# STM32WL5X_CM4 register map
File version: 2.2
CPU: CM4 r0p1, little endian, MPU, no FPU, 4 interrupt priority bits
Registers are 32-bit, read-write, reset 0x0 unless marked. A register's access mark holds for its fields unless they carry their own. Offsets are from the block's base; [hi:lo] are bit positions; lines under a group give offsets from that group; {n}, {i} and the like mark numbered series; 'fields as' and 'values as' point back to an identical list.

## DMA1 — Direct memory access controller
Base 0x40020000
Same registers: DMA2 0x40020400
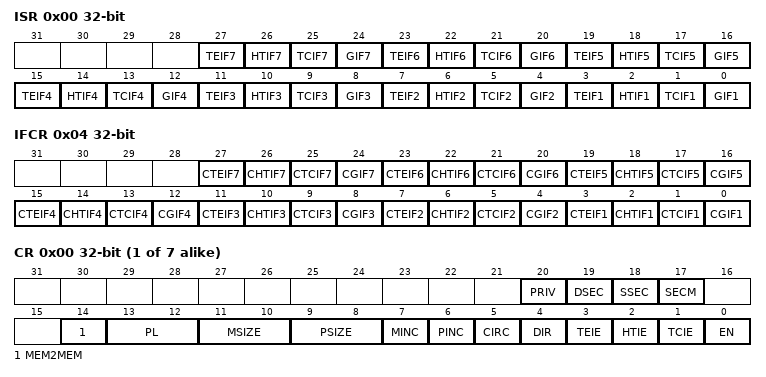
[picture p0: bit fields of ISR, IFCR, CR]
0x00 ISR ro — interrupt status register
  [4n-1] TEIF{n} (n=1..7) — Channel {n} Transfer Error flag
    0=NoError (No transfer error); 1=Error (A transfer error has occured)
  [4n-2] HTIF{n} (n=1..7) — Channel {n} Half Transfer Complete flag
    0=NotHalf (No half transfer event); 1=Half (A half transfer event has occured)
  [4n-3] TCIF{n} (n=1..7) — Channel {n} Transfer Complete flag
    0=NotComplete (No transfer complete event); 1=Complete (A transfer complete event has occured)
  [4n-4] GIF{n} (n=1..7) — Channel {n} Global interrupt flag
    0=NoEvent (No transfer error, half event, complete event); 1=Event (A transfer error, half event or complete event has occured)
0x04 IFCR wo — interrupt flag clear register
  [4n-1] CTEIF{n} (n=1..7) — Channel {n} Transfer Error clear
    1=Clears the TEIF flag in the ISR register
  [4n-2] CHTIF{n} (n=1..7) — Channel {n} Half Transfer clear
    1=Clears the HTIF flag in the ISR register
  [4n-3] CTCIF{n} (n=1..7) — Channel {n} Transfer Complete clear
    1=Clears the TCIF flag in the ISR register
  [4n-4] CGIF{n} (n=1..7) — Channel {n} Global interrupt clear
    1=Clears the GIF, TEIF, HTIF, TCIF flags in the ISR register
0x08 CH{i} (i=1..7; step 0x14) group — Channel cluster: CCR?, CNDTR?, CPAR?, and CMAR? registers
  0x00 CR — channel x configuration register
    [20] PRIV — rivileged mode
      0=Disabled; 1=Enabled
    [19] DSEC — ecurity of the DMA transfer to the destination
    [18] SSEC — ecurity of the DMA transfer from the source
    [17] SECM — ecure mode
    [14] MEM2MEM — memory-to-memory mode
      0=Disabled (Memory to memory mode disabled); 1=Enabled (Memory to memory mode enabled)
    [13:12] PL — priority level
      0=Low (Low priority); 1=Medium priority; 2=High priority; 3=Very high priority
    [11:10] MSIZE — memory size
      0=Bits8 (8-bit size); 1=Bits16 (16-bit size); 2=Bits32 (32-bit size)
    [9:8] PSIZE — peripheral size
      values as MSIZE
    [7] MINC — memory increment mode
      0=Disabled (Increment mode disabled); 1=Enabled (Increment mode enabled)
    [6] PINC — peripheral increment mode
      values as MINC
    [5] CIRC — circular mode
      0=Disabled (Circular buffer disabled); 1=Enabled (Circular buffer enabled)
    [4] DIR — data transfer direction
      0=FromPeripheral (Read from peripheral); 1=FromMemory (Read from memory)
    [3] TEIE — transfer error interrupt enable
      0=Disabled (Transfer Error interrupt disabled); 1=Enabled (Transfer Error interrupt enabled)
    [2] HTIE — half transfer interrupt enable
      0=Disabled (Half Transfer interrupt disabled); 1=Enabled (Half Transfer interrupt enabled)
    [1] TCIE — transfer complete interrupt enable
      0=Disabled (Transfer Complete interrupt disabled); 1=Enabled (Transfer Complete interrupt enabled)
    [0] EN — channel enable
      0=Disabled (Channel disabled); 1=Enabled (Channel enabled)
  0x04 NDTR — channel x number of data to transfer register
    [17:0] NDT — number of data to transfer (0 to 218 - 1)
  0x08 PAR — channel x peripheral address register
    [31:0] PA — peripheral address
  0x0C MAR — channel x memory address register
    [31:0] MA — peripheral address

## GPIOA — General-purpose I/Os
Base 0x48000000
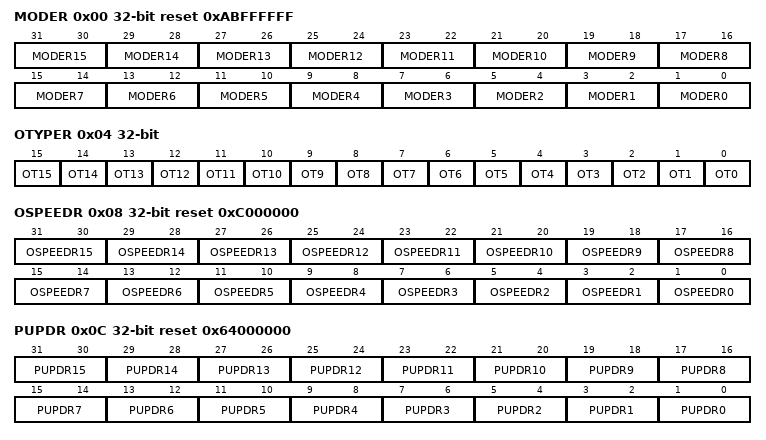
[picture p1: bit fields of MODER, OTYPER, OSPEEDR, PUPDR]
0x00 MODER reset 0xABFFFFFF — GPIO port mode register
  [2n+1:2n] MODER{n} (n=0..15) — Port x configuration pin {n}
    0=Input mode (reset state); 1=Output (General purpose output mode); 2=Alternate function mode; 3=Analog mode
0x04 OTYPER — GPIO port output type register
  [n] OT{n} (n=0..15) — Port x configuration pin {n}
    0=PushPull (Output push-pull (reset state)); 1=OpenDrain (Output open-drain)
0x08 OSPEEDR reset 0xC000000 — GPIO port output speed register
  [2n+1:2n] OSPEEDR{n} (n=0..15) — Port x configuration pin {n}
    0=LowSpeed; 1=MediumSpeed; 2=HighSpeed; 3=VeryHighSpeed
0x0C PUPDR reset 0x64000000 — GPIO port pull-up/pull-down register
  [2n+1:2n] PUPDR{n} (n=0..15) — Port x configuration pin {n}
    0=Floating (No pull-up, pull-down); 1=PullUp; 2=PullDown
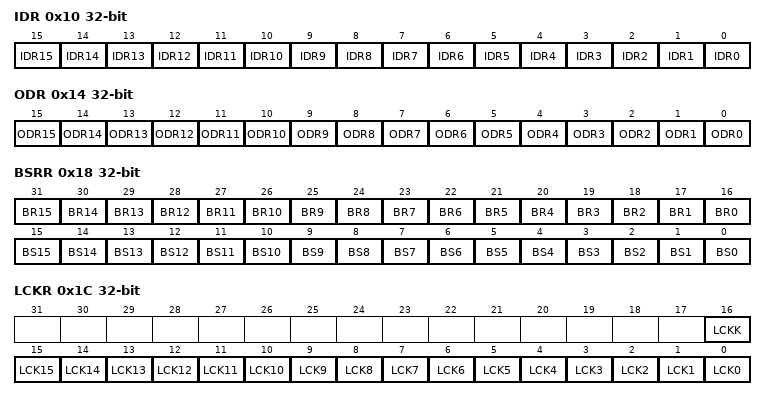
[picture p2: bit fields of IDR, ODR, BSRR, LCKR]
0x10 IDR ro — GPIO port input data register
  [n] IDR{n} (n=0..15) — Port input data pin {n}
    0=Low (Input is logic low); 1=High (Input is logic high)
0x14 ODR — GPIO port output data register
  [n] ODR{n} (n=0..15) — Port output data pin {n}
    0=Low (Set output to logic low); 1=High (Set output to logic high)
0x18 BSRR wo — GPIO port bit set/reset register
  [n+16] BR{n} (n=0..15) — Port x reset pin {n}
    1=Resets the corresponding ODRx bit
  [n] BS{n} (n=0..15) — Port x set pin {n}
    1=Set (Sets the corresponding ODRx bit)
0x1C LCKR — GPIO port configuration lock register
  [16] LCKK — Port x lock bit y (y= 0..15)
    0=NotActive (Port configuration lock key not active); 1=Active (Port configuration lock key active)
  [n] LCK{n} (n=0..15) — Port x lock pin {n}
    0=Unlocked (Port configuration not locked); 1=Locked (Port configuration locked)
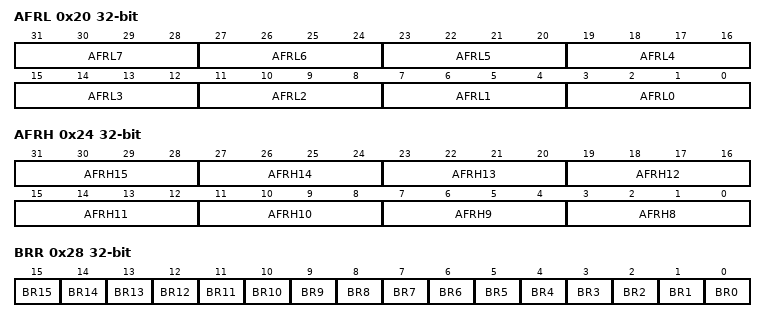
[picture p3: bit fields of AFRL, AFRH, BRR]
0x20 AFRL — GPIO alternate function low register
  [3:0] AFR{x} (x=L0,L1,L2,L3,L4,L5,L6,L7; step 4) — Alternate function selection for port x bit y (y = 0..7)
    {v}=AF{v} (v=0..15)
0x24 AFRH — GPIO alternate function high register
  [3:0] AFR{x} (x=H8,H9,H10,H11,H12,H13,H14,H15; step 4) — Alternate function selection for port x bit y (y = 8..15)
    {v}=AF{v} (v=0..15)
0x28 BRR — GPIO port bit reset register
  [n] BR{n} (n=0..15) — Port x reset pin {n}
    on write: 0=No action on the corresponding ODx bit; 1=Reset the ODx bit

## GPIOB — General-purpose I/Os
Base 0x48000400
Registers as GPIOA; these are added or differ:
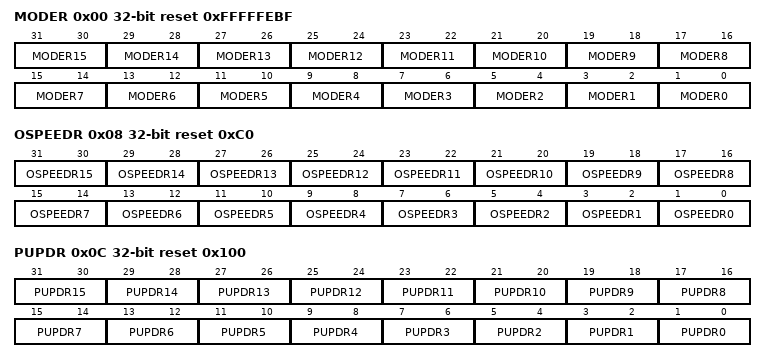
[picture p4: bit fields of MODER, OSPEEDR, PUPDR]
0x00 MODER reset 0xFFFFFEBF — GPIO port mode register
  [2n+1:2n] MODER{n} (n=0..15) — Port x configuration pin {n}
    0=Input mode (reset state); 1=Output (General purpose output mode); 2=Alternate function mode; 3=Analog mode
0x08 OSPEEDR reset 0xC0 — GPIO port output speed register
  [2n+1:2n] OSPEEDR{n} (n=0..15) — Port x configuration pin {n}
    0=LowSpeed; 1=MediumSpeed; 2=HighSpeed; 3=VeryHighSpeed
0x0C PUPDR reset 0x100 — GPIO port pull-up/pull-down register
  [2n+1:2n] PUPDR{n} (n=0..15) — Port x configuration pin {n}
    0=Floating (No pull-up, pull-down); 1=PullUp; 2=PullDown
